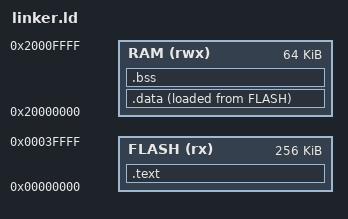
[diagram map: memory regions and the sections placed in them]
ENTRY(Reset_Handler)

MEMORY
{
  FLASH (rx)  : ORIGIN = 0x00000000, LENGTH = 256K
  RAM (rwx)   : ORIGIN = 0x20000000, LENGTH = 64K
}

SECTIONS
{
  .text : {
    KEEP(*(.vector_table))
    *(.text*)
    . = ALIGN(4);
  } > FLASH

  .data : {
    . = ALIGN(4);
    _sdata = .;
    *(.data*)
    . = ALIGN(4);
    _edata = .;
  } > RAM AT > FLASH
  _sidata = LOADADDR(.data);

  .bss (NOLOAD) : {
    . = ALIGN(4);
    _sbss = .;
    *(.bss*)
    *(COMMON)
    . = ALIGN(4);
    _ebss = .;
  } > RAM

  _stack_top = ORIGIN(RAM) + LENGTH(RAM);
}
